# R7KA8M2AD register map
Vendor: Renesas Electronics Corporation; Series: RA8; File version: 1.10.02
CPU: CM85 r0p2, little endian, MPU, FPU, VTOR, 4 interrupt priority bits, 96 interrupts
Registers are 32-bit, read-write, reset 0x0 unless marked. A register's access mark holds for its fields unless they carry their own. Offsets are from the block's base; [hi:lo] are bit positions; {n}, {i} and the like mark numbered series; <NAME> marks a mode.

## DAC0_B — 12-bit D/A converter
Base 0x40233000
Same registers: DAC1_B 0x40233100, DAC0_B_NS 0x50233000, DAC1_B_NS 0x50233100
0x00 DADR 16-bit — D/A Data Register
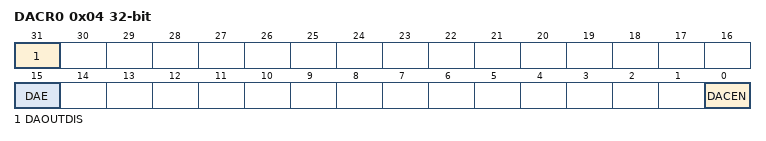
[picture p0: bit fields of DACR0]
0x04 DACR0 — D/A Control 0 Register
  [31] DAOUTDIS — Analog Output Disables
    0=The output to pin is enabled and the output to comparator is disabled; 1=The output to pin is disabled and the output to comparator is enabled
  [15] DAE — D/A Enable R/W
    0=Control D/A conversion of channels 0 and 1 individually; 1=Control D/A conversion of channels 0 and 1 collectively
  [0] DACEN — D/A Output Enable
    0=Disable analog output of channel n (DAn); 1=Enable D/A conversion of channel n (DAn)
0x08 DACR1 — D/A Control 1 Register
  [16] DPSEL — DADR Format Select R/W
    0=Right-justified format; 1=Left-justified format
0x0C DACR2 — D/A Control 2 Register
  [8] OFSSEL — DAC Operating Voltage Mode Selection
    0=Normal voltage mode (VREFH ≥ 2.7 V); 1=Low voltage mode (VREFH < 2.7 V)

## TSN — Temperature Sensor
Base 0x40235000
Same registers: TSN_NS 0x50235000
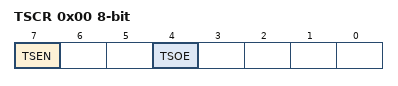
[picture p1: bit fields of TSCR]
0x00 TSCR 8-bit — Temperature Sensor Control Register
  [7] TSEN — Temperature Sensor Enable
    0=Stop the temperature sensor; 1=Start the temperature sensor
  [4] TSOE — Temperature Sensor Output Enable
    0=Disable output from the temperature sensor to the ADC16H; 1=Enable output from the temperature sensor to the ADC16H

## ACMPHS0 — High-Speed Analog Comparator
Base 0x40236000
Same registers: ACMPHS1 0x40236100, ACMPHS2 0x40236200, ACMPHS3 0x40236300, ACMPHS0_NS 0x50236000, ACMPHS1_NS 0x50236100, ACMPHS2_NS 0x50236200, ACMPHS3_NS 0x50236300
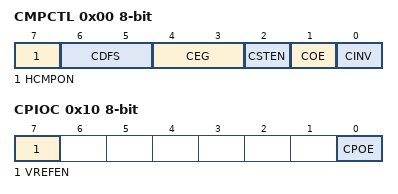
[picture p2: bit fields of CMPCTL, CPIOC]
0x00 CMPCTL 8-bit — Comparator Control Register
  [7] HCMPON — Comparator Operation Control
    0=Stop operation (comparator outputs a low-level signal); 1=Enable operation (enables input to the comparator pins)
  [6:5] CDFS — Noise Filter Selection
    0=Do not use noise filter; 1=Use noise filter sampling frequency of PCLKB/23; 2=Use noise filter sampling frequency of PCLKB/24; 3=Use noise filter sampling frequency of PCLKB/25
  [4:3] CEG — Selection of Valid Edge (Edge Selector)
    0=Do not detect edge; 1=Detect rising edge; 2=Detect falling edge; 3=Detect both edges
  [2] CSTEN — Interrupt Select
    0=Output through the edge selector; 1=Output directly
  [1] COE — Comparator Output Enable
    0=Disable comparator output (output signal is low level); 1=Enable comparator output
  [0] CINV — Comparator Output Polarity Selection
    0=Do not invert comparator output; 1=Invert comparator output
0x04 CMPSEL0 8-bit — Comparator Input Select Register
  [3:0] CMPSEL — Comparator Input Selection
    0=Do not input; 1=Select IVCMP0; 2=Select IVCMP1; 4=Select IVCMP2; 8=Select IVCMP3; other=Others (Setting prohibited)
0x08 CMPSEL1 8-bit — Comparator Reference Voltage Select Register
  [3:0] CRVS — Reference Voltage Selection
    0=Do not input; 1=Select IVREF0; 2=Select IVREF1; 4=Select IVREF2; 8=Select IVREF3; other=Others (Setting prohibited)
0x0C CMPMON 8-bit ro — Comparator Output Monitor Register
  [0] COMPMON — Comparator Output Monitor
    0=Comparator output is low; 1=Comparator output is high
0x10 CPIOC 8-bit — Comparator Output Control Register
  [7] VREFEN
    0=Disable internal Vref; 1=Enable internal Vref
  [0] CPOE — External Pin Output Enable
    0=Output to the comparator external pin is disabled (the output signal is fixed to low); 1=Output to the comparator external pin is enabled
0x40 CPINTCTL 8-bit — Comparator Interrupt Control Register
  [0] MSKE — Comparator Interrupt Periodic Mask Enable
    0=Disable interrupt masking (Default); 1=Enable interrupt masking by GPT output signal selected by CPMSKCTL.MSKSEL[2:0]
0x44 CPMSKCTL 8-bit — Comparator Interrupt Mask Control Register
  [2:0] MSKSEL — Comparator Interrupt Periodic Mask Selection
    {v}=Enable interrupt masking by GTIOC{v}A output signal (v=0..7)
